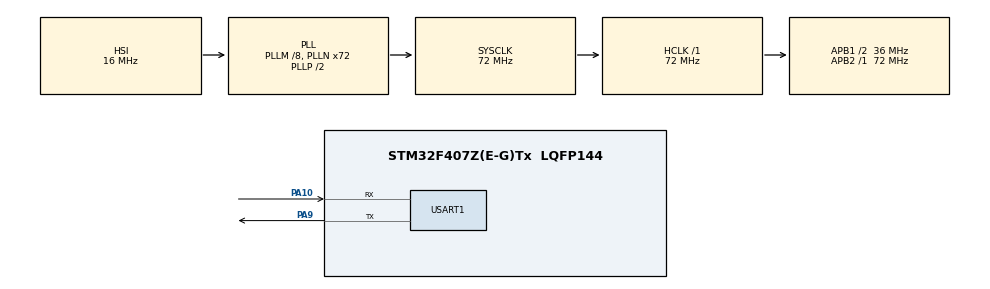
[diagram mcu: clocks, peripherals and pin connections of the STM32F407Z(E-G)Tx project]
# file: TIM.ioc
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Mcu.Family=STM32F4
Mcu.Name=STM32F407Z(E-G)Tx
Mcu.Package=LQFP144
NVIC.PriorityGroup=NVIC_PRIORITYGROUP_4
NVIC.TIM1_UP_TIM10_IRQn=true\:0\:0\:false\:false\:true\:true\:true\:true
NVIC.TIM2_IRQn=true\:0\:0\:false\:false\:true\:true\:true\:true
NVIC.USART1_IRQn=true\:0\:0\:false\:false\:true\:true\:true\:true
PA10.Mode=Asynchronous
PA10.Signal=USART1_RX
PA9.Mode=Asynchronous
PA9.Signal=USART1_TX
ProjectManager.HeapSize=0x200
ProjectManager.StackSize=0x400
ProjectManager.TargetToolchain=MDK-ARM V5.32
RCC.48MHZClocksFreq_Value=36000000
RCC.AHBFreq_Value=72000000
RCC.APB1CLKDivider=RCC_HCLK_DIV2
RCC.APB1Freq_Value=36000000
RCC.APB1TimFreq_Value=72000000
RCC.APB2Freq_Value=72000000
RCC.APB2TimFreq_Value=72000000
RCC.CortexFreq_Value=72000000
RCC.HCLKFreq_Value=72000000
RCC.HSE_VALUE=25000000
RCC.HSI_VALUE=16000000
RCC.LSE_VALUE=32768
RCC.PLLM=8
RCC.PLLN=72
RCC.SYSCLKFreq_VALUE=72000000
RCC.SYSCLKSource=RCC_SYSCLKSOURCE_PLLCLK
RCC.VCOOutputFreq_Value=144000000
TIM1.AutoReloadPreload=TIM_AUTORELOAD_PRELOAD_ENABLE
TIM1.Period=1000-1
TIM1.Prescaler=72-1
TIM2.AutoReloadPreload=TIM_AUTORELOAD_PRELOAD_ENABLE
TIM2.Period=1000-1
TIM2.Prescaler=72-1
USART1.VirtualMode=VM_ASYNC
VP_TIM1_VS_ClockSourceINT.Mode=Internal
VP_TIM2_VS_ClockSourceINT.Mode=Internal
board=custom

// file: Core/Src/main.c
/* USER CODE BEGIN Header */
/**
  ******************************************************************************
  * @file           : main.c
  * @brief          : Main program body
  ******************************************************************************
  * @attention
  *
  * Copyright (c) 2024 STMicroelectronics.
  * All rights reserved.
  *
  * This software is licensed under terms that can be found in the LICENSE file
  * in the root directory of this software component.
  * If no LICENSE file comes with this software, it is provided AS-IS.
  *
  ******************************************************************************
  */
/* USER CODE END Header */
#include "main.h"
#include "tim.h"
#include "usart.h"
#include "gpio.h"

/* USER CODE BEGIN Includes */
#include <stdio.h>
/* USER CODE END Includes */

void SystemClock_Config(void);

/* USER CODE BEGIN 0 */
int tim1 = 0;
int tim2 = 0;

int fputc(int ch,FILE *f)
{
    uint8_t temp[1]={ch};
    HAL_UART_Transmit(&huart1, temp, 1, 2);
	return ch;
}
/* USER CODE END 0 */

int main(void)
{

  /* MCU Configuration--------------------------------------------------------*/

  /* Reset of all peripherals, Initializes the Flash interface and the Systick. */
  HAL_Init();

  /* Configure the system clock */
  SystemClock_Config();

  /* Initialize all configured peripherals */
  MX_GPIO_Init();
  MX_TIM1_Init();
  MX_TIM2_Init();
  MX_USART1_UART_Init();

  /* Infinite loop */
  /* USER CODE BEGIN WHILE */
  printf("program running");
  HAL_TIM_Base_Start_IT(&htim1); //定时器1使能
  HAL_TIM_Base_Start_IT(&htim2); //定时器2使能
  while (1)
  {

	  printf("tim1 = %d",tim1);
	  printf("tim2 = %d",tim2);
    /* USER CODE END WHILE */

  }
}

void SystemClock_Config(void)
{
  RCC_OscInitTypeDef RCC_OscInitStruct = {0};
  RCC_ClkInitTypeDef RCC_ClkInitStruct = {0};

  /** Configure the main internal regulator output voltage
  */
  __HAL_RCC_PWR_CLK_ENABLE();
  __HAL_PWR_VOLTAGESCALING_CONFIG(PWR_REGULATOR_VOLTAGE_SCALE1);

  /** Initializes the RCC Oscillators according to the specified parameters
  * in the RCC_OscInitTypeDef structure.
  */
  RCC_OscInitStruct.OscillatorType = RCC_OSCILLATORTYPE_HSI;
  RCC_OscInitStruct.HSIState = RCC_HSI_ON;
  RCC_OscInitStruct.HSICalibrationValue = RCC_HSICALIBRATION_DEFAULT;
  RCC_OscInitStruct.PLL.PLLState = RCC_PLL_ON;
  RCC_OscInitStruct.PLL.PLLSource = RCC_PLLSOURCE_HSI;
  RCC_OscInitStruct.PLL.PLLM = 8;
  RCC_OscInitStruct.PLL.PLLN = 72;
  RCC_OscInitStruct.PLL.PLLP = RCC_PLLP_DIV2;
  RCC_OscInitStruct.PLL.PLLQ = 4;
  if (HAL_RCC_OscConfig(&RCC_OscInitStruct) != HAL_OK)
  {
    Error_Handler();
  }

  /** Initializes the CPU, AHB and APB buses clocks
  */
  RCC_ClkInitStruct.ClockType = RCC_CLOCKTYPE_HCLK|RCC_CLOCKTYPE_SYSCLK
                              |RCC_CLOCKTYPE_PCLK1|RCC_CLOCKTYPE_PCLK2;
  RCC_ClkInitStruct.SYSCLKSource = RCC_SYSCLKSOURCE_PLLCLK;
  RCC_ClkInitStruct.AHBCLKDivider = RCC_SYSCLK_DIV1;
  RCC_ClkInitStruct.APB1CLKDivider = RCC_HCLK_DIV2;
  RCC_ClkInitStruct.APB2CLKDivider = RCC_HCLK_DIV1;

  if (HAL_RCC_ClockConfig(&RCC_ClkInitStruct, FLASH_LATENCY_2) != HAL_OK)
  {
    Error_Handler();
  }
}

/* USER CODE BEGIN 4 */
void HAL_TIM_PeriodElapsedCallback(TIM_HandleTypeDef *htim) {
  if (htim->Instance == TIM1) {
    // 定时器1中断业务
	 tim1++;
  }
  if (htim->Instance == TIM2) {
    // 定时器2中断业务
    tim2++;
  }
}

void HAL_UART_RxCpltCallback(UART_HandleTypeDef *huart) {
if(huart -> Instance == huart1.Instance ) {
  printf("UART handle running");
}
}
/* USER CODE END 4 */

void Error_Handler(void)
{
  __disable_irq();
  while (1)
  {
  }
}
